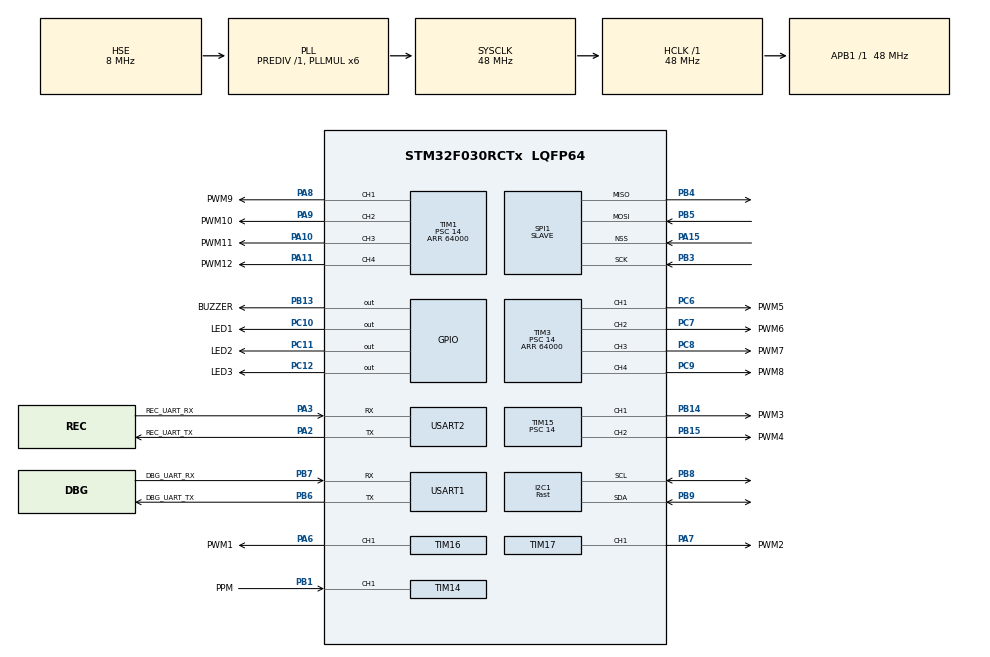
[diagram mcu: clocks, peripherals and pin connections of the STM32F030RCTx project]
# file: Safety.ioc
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I2C1.I2C_Speed_Mode=I2C_Fast
I2C1.Timing=0x0000020B
Mcu.Family=STM32F0
Mcu.Name=STM32F030RCTx
Mcu.Package=LQFP64
NVIC.SPI1_IRQn=true\:0\:0\:false\:false\:true\:true
NVIC.TIM14_IRQn=true\:1\:0\:true\:false\:true\:true
PA10.GPIO_Label=PWM11
PA10.Signal=S_TIM1_CH3
PA11.GPIO_Label=PWM12
PA11.Signal=S_TIM1_CH4
PA13.Mode=Serial_Wire
PA13.Signal=SYS_SWDIO
PA14.Mode=Serial_Wire
PA14.Signal=SYS_SWCLK
PA15.Mode=NSS_Signal_Hard_Input
PA15.Signal=SPI1_NSS
PA2.GPIO_Label=REC_UART_TX
PA2.Mode=Asynchronous
PA2.Signal=USART2_TX
PA3.GPIO_Label=REC_UART_RX
PA3.Mode=Asynchronous
PA3.Signal=USART2_RX
PA6.GPIO_Label=PWM1
PA6.Signal=S_TIM16_CH1
PA7.GPIO_Label=PWM2
PA7.Signal=S_TIM17_CH1
PA8.GPIO_Label=PWM9
PA8.Signal=S_TIM1_CH1
PA9.GPIO_Label=PWM10
PA9.Signal=S_TIM1_CH2
PB1.GPIO_Label=PPM
PB1.GPIO_ModeDefaultPP=GPIO_MODE_AF_PP
PB1.Signal=S_TIM14_CH1
PB13.GPIO_Label=BUZZER
PB13.Signal=GPIO_Output
PB14.GPIO_Label=PWM3
PB14.Signal=S_TIM15_CH1
PB15.GPIO_Label=PWM4
PB15.Signal=S_TIM15_CH2
PB3.Mode=Full_Duplex_Slave
PB3.Signal=SPI1_SCK
PB4.Mode=Full_Duplex_Slave
PB4.Signal=SPI1_MISO
PB5.Mode=Full_Duplex_Slave
PB5.Signal=SPI1_MOSI
PB6.GPIO_Label=DBG_UART_TX
PB6.GPIO_Speed=GPIO_SPEED_FREQ_HIGH
PB6.Mode=Asynchronous
PB6.Signal=USART1_TX
PB7.GPIO_Label=DBG_UART_RX
PB7.Mode=Asynchronous
PB7.Signal=USART1_RX
PB8.Mode=I2C
PB8.Signal=I2C1_SCL
PB9.Mode=I2C
PB9.Signal=I2C1_SDA
PC10.GPIO_Label=LED1
PC10.Signal=GPIO_Output
PC11.GPIO_Label=LED2
PC11.Signal=GPIO_Output
PC12.GPIO_Label=LED3
PC12.Signal=GPIO_Output
PC14OSC32_IN.Mode=LSE-External-Oscillator
PC14OSC32_IN.Signal=RCC_OSC32_IN
PC15OSC32_OUT.Mode=LSE-External-Oscillator
PC15OSC32_OUT.Signal=RCC_OSC32_OUT
PC6.GPIO_Label=PWM5
PC6.Signal=S_TIM3_CH1
PC7.GPIO_Label=PWM6
PC7.Signal=S_TIM3_CH2
PC8.GPIO_Label=PWM7
PC8.Signal=S_TIM3_CH3
PC9.GPIO_Label=PWM8
PC9.Signal=S_TIM3_CH4
PF0-OSC_IN.Mode=HSE-External-Oscillator
PF0-OSC_IN.Signal=RCC_OSC_IN
PF1-OSC_OUT.Mode=HSE-External-Oscillator
PF1-OSC_OUT.Signal=RCC_OSC_OUT
ProjectManager.HeapSize=0x200
ProjectManager.StackSize=0x400
ProjectManager.TargetToolchain=Makefile
RCC.AHBFreq_Value=48000000
RCC.APB1Freq_Value=48000000
RCC.APB1TimFreq_Value=48000000
RCC.HCLKFreq_Value=48000000
RCC.PLLMUL=RCC_PLL_MUL6
RCC.PLLSourceVirtual=RCC_PLLSOURCE_HSE
RCC.SYSCLKFreq_VALUE=48000000
RCC.SYSCLKSource=RCC_SYSCLKSOURCE_PLLCLK
SH.S_TIM14_CH1.0=TIM14_CH1,Input_Capture1_from_TI1
SH.S_TIM15_CH1.0=TIM15_CH1,PWM Generation1 CH1
SH.S_TIM15_CH2.0=TIM15_CH2,PWM Generation2 CH2
SH.S_TIM16_CH1.0=TIM16_CH1,PWM Generation1 CH1
SH.S_TIM17_CH1.0=TIM17_CH1,PWM Generation1 CH1
SH.S_TIM1_CH1.0=TIM1_CH1,PWM Generation1 CH1
SH.S_TIM1_CH2.0=TIM1_CH2,PWM Generation2 CH2
SH.S_TIM1_CH3.0=TIM1_CH3,PWM Generation3 CH3
SH.S_TIM1_CH4.0=TIM1_CH4,PWM Generation4 CH4
SH.S_TIM3_CH1.0=TIM3_CH1,PWM Generation1 CH1
SH.S_TIM3_CH2.0=TIM3_CH2,PWM Generation2 CH2
SH.S_TIM3_CH3.0=TIM3_CH3,PWM Generation3 CH3
SH.S_TIM3_CH4.0=TIM3_CH4,PWM Generation4 CH4
SPI1.CRCCalculation=SPI_CRCCALCULATION_DISABLE
SPI1.DataSize=SPI_DATASIZE_16BIT
SPI1.Direction=SPI_DIRECTION_2LINES
SPI1.Mode=SPI_MODE_SLAVE
SPI1.TIMode=SPI_TIMODE_DISABLE
SPI1.VirtualNSS=VM_NSSHARD
SPI1.VirtualType=VM_SLAVE
TIM1.Channel-PWM\ Generation1\ CH1=TIM_CHANNEL_1
TIM1.Channel-PWM\ Generation2\ CH2=TIM_CHANNEL_2
TIM1.Channel-PWM\ Generation3\ CH3=TIM_CHANNEL_3
TIM1.Channel-PWM\ Generation4\ CH4=TIM_CHANNEL_4
TIM1.OCMode_PWM-PWM\ Generation1\ CH1=TIM_OCMODE_PWM1
TIM1.OCMode_PWM-PWM\ Generation2\ CH2=TIM_OCMODE_PWM1
TIM1.OCMode_PWM-PWM\ Generation3\ CH3=TIM_OCMODE_PWM1
TIM1.OCMode_PWM-PWM\ Generation4\ CH4=TIM_OCMODE_PWM1
TIM1.Period=64000
TIM1.Prescaler=14
TIM1.TIM_MasterSlaveMode=TIM_MASTERSLAVEMODE_DISABLE
TIM14.Channel=TIM_CHANNEL_1
TIM14.Period=48000
TIM14.Prescaler=2
TIM15.Channel-PWM\ Generation1\ CH1=TIM_CHANNEL_1
TIM15.Channel-PWM\ Generation2\ CH2=TIM_CHANNEL_2
TIM15.OCMode_PWM-PWM\ Generation1\ CH1=TIM_OCMODE_PWM1
TIM15.OCMode_PWM-PWM\ Generation2\ CH2=TIM_OCMODE_PWM1
TIM15.Period=64000
TIM15.Prescaler=14
TIM16.Channel=TIM_CHANNEL_1
TIM16.OCMode_PWM=TIM_OCMODE_PWM1
TIM16.Period=64000
TIM16.Prescaler=14
TIM17.Channel=TIM_CHANNEL_1
TIM17.OCMode_PWM=TIM_OCMODE_PWM1
TIM17.Period=64000
TIM17.Prescaler=14
TIM3.Channel-PWM\ Generation1\ CH1=TIM_CHANNEL_1
TIM3.Channel-PWM\ Generation2\ CH2=TIM_CHANNEL_2
TIM3.Channel-PWM\ Generation3\ CH3=TIM_CHANNEL_3
TIM3.Channel-PWM\ Generation4\ CH4=TIM_CHANNEL_4
TIM3.OCMode_PWM-PWM\ Generation1\ CH1=TIM_OCMODE_PWM1
TIM3.OCMode_PWM-PWM\ Generation2\ CH2=TIM_OCMODE_PWM1
TIM3.OCMode_PWM-PWM\ Generation3\ CH3=TIM_OCMODE_PWM1
TIM3.OCMode_PWM-PWM\ Generation4\ CH4=TIM_OCMODE_PWM1
TIM3.Period=64000
TIM3.Prescaler=14
USART1.SwapParam=ADVFEATURE_SWAP_ENABLE
USART1.VirtualMode-Asynchronous=VM_ASYNC
USART1.WordLength=WORDLENGTH_8B
USART2.VirtualMode-Asynchronous=VM_ASYNC
USART2.WordLength=WORDLENGTH_8B
VP_IWDG_VS_IWDG.Mode=IWDG_Activate
VP_TIM14_VS_ClockSourceINT.Mode=Enable_Timer
VP_TIM15_VS_ClockSourceINT.Mode=Internal
VP_TIM16_VS_ClockSourceINT.Mode=Enable_Timer
VP_TIM17_VS_ClockSourceINT.Mode=Enable_Timer
VP_TIM1_VS_ClockSourceINT.Mode=Internal
VP_TIM3_VS_ClockSourceINT.Mode=Internal
board=Safety

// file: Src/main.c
/**
  ******************************************************************************
  * File Name          : main.c
  * Description        : Main program body
  ******************************************************************************
  ** This notice applies to any and all portions of this file
  * that are not between comment pairs USER CODE BEGIN and
  * USER CODE END. Other portions of this file, whether
  * inserted by the user or by software development tools
  * are owned by their respective copyright owners.
  *
  * COPYRIGHT(c) 2017 STMicroelectronics
  *
  * Redistribution and use in source and binary forms, with or without modification,
  * are permitted provided that the following conditions are met:
  *   1. Redistributions of source code must retain the above copyright notice,
  *      this list of conditions and the following disclaimer.
  *   2. Redistributions in binary form must reproduce the above copyright notice,
  *      this list of conditions and the following disclaimer in the documentation
  *      and/or other materials provided with the distribution.
  *   3. Neither the name of STMicroelectronics nor the names of its contributors
  *      may be used to endorse or promote products derived from this software
  *      without specific prior written permission.
  *
  * THIS SOFTWARE IS PROVIDED BY THE COPYRIGHT HOLDERS AND CONTRIBUTORS "AS IS"
  * AND ANY EXPRESS OR IMPLIED WARRANTIES, INCLUDING, BUT NOT LIMITED TO, THE
  * IMPLIED WARRANTIES OF MERCHANTABILITY AND FITNESS FOR A PARTICULAR PURPOSE ARE
  * DISCLAIMED. IN NO EVENT SHALL THE COPYRIGHT HOLDER OR CONTRIBUTORS BE LIABLE
  * FOR ANY DIRECT, INDIRECT, INCIDENTAL, SPECIAL, EXEMPLARY, OR CONSEQUENTIAL
  * DAMAGES (INCLUDING, BUT NOT LIMITED TO, PROCUREMENT OF SUBSTITUTE GOODS OR
  * SERVICES; LOSS OF USE, DATA, OR PROFITS; OR BUSINESS INTERRUPTION) HOWEVER
  * CAUSED AND ON ANY THEORY OF LIABILITY, WHETHER IN CONTRACT, STRICT LIABILITY,
  * OR TORT (INCLUDING NEGLIGENCE OR OTHERWISE) ARISING IN ANY WAY OUT OF THE USE
  * OF THIS SOFTWARE, EVEN IF ADVISED OF THE POSSIBILITY OF SUCH DAMAGE.
  *
  ******************************************************************************
  */

#include "main.h"
#include "stm32f0xx_hal.h"
#include "i2c.h"
#include "iwdg.h"
#include "spi.h"
#include "tim.h"
#include "usart.h"
#include "gpio.h"

/* USER CODE BEGIN Includes */
#include "debug.h"
#include "safety_control.h"

/* USER CODE END Includes */

/* USER CODE BEGIN PV */
/* Private variables ---------------------------------------------------------*/

/* USER CODE END PV */

void SystemClock_Config(void);

/* USER CODE BEGIN PFP */
/* Private function prototypes -----------------------------------------------*/

/* USER CODE END PFP */

int main(void)
{

  /* MCU Configuration----------------------------------------------------------*/

  /* Reset of all peripherals, Initializes the Flash interface and the Systick. */
  HAL_Init();

  /* Configure the system clock */
  SystemClock_Config();

  /* Initialize all configured peripherals */
  MX_GPIO_Init();
  MX_I2C1_Init();
  MX_SPI1_Init();
  MX_TIM1_Init();
  MX_TIM3_Init();
  MX_TIM14_Init();
  MX_TIM15_Init();
  MX_TIM16_Init();
  MX_TIM17_Init();
  MX_USART1_UART_Init();
  MX_USART2_UART_Init();
  MX_IWDG_Init();

  /* USER CODE BEGIN 2 */

  debug("\r\n\r\nStarting up...");
  debug("Compiled on %s at %s", __DATE__, __TIME__);

  HAL_GPIO_WritePin(LED1_GPIO_Port, LED1_Pin, GPIO_PIN_RESET);
  HAL_GPIO_WritePin(LED2_GPIO_Port, LED2_Pin, GPIO_PIN_SET);
  HAL_GPIO_WritePin(LED3_GPIO_Port, LED3_Pin, GPIO_PIN_SET);

  Safety_Init();
  Safety_Run();
  /* USER CODE END 2 */

  /* Infinite loop */
  while (1)
  {

  }

}

/** System Clock Configuration
*/
void SystemClock_Config(void)
{

  RCC_OscInitTypeDef RCC_OscInitStruct;
  RCC_ClkInitTypeDef RCC_ClkInitStruct;
  RCC_PeriphCLKInitTypeDef PeriphClkInit;

    /**Initializes the CPU, AHB and APB busses clocks
    */
  RCC_OscInitStruct.OscillatorType = RCC_OSCILLATORTYPE_HSI|RCC_OSCILLATORTYPE_LSI
                              |RCC_OSCILLATORTYPE_HSE;
  RCC_OscInitStruct.HSEState = RCC_HSE_ON;
  RCC_OscInitStruct.HSIState = RCC_HSI_ON;
  RCC_OscInitStruct.HSICalibrationValue = 16;
  RCC_OscInitStruct.LSIState = RCC_LSI_ON;
  RCC_OscInitStruct.PLL.PLLState = RCC_PLL_ON;
  RCC_OscInitStruct.PLL.PLLSource = RCC_PLLSOURCE_HSE;
  RCC_OscInitStruct.PLL.PLLMUL = RCC_PLL_MUL6;
  RCC_OscInitStruct.PLL.PREDIV = RCC_PREDIV_DIV1;
  if (HAL_RCC_OscConfig(&RCC_OscInitStruct) != HAL_OK)
  {
    _Error_Handler(__FILE__, __LINE__);
  }

    /**Initializes the CPU, AHB and APB busses clocks
    */
  RCC_ClkInitStruct.ClockType = RCC_CLOCKTYPE_HCLK|RCC_CLOCKTYPE_SYSCLK
                              |RCC_CLOCKTYPE_PCLK1;
  RCC_ClkInitStruct.SYSCLKSource = RCC_SYSCLKSOURCE_PLLCLK;
  RCC_ClkInitStruct.AHBCLKDivider = RCC_SYSCLK_DIV1;
  RCC_ClkInitStruct.APB1CLKDivider = RCC_HCLK_DIV1;

  if (HAL_RCC_ClockConfig(&RCC_ClkInitStruct, FLASH_LATENCY_1) != HAL_OK)
  {
    _Error_Handler(__FILE__, __LINE__);
  }

  PeriphClkInit.PeriphClockSelection = RCC_PERIPHCLK_USART1|RCC_PERIPHCLK_I2C1;
  PeriphClkInit.Usart1ClockSelection = RCC_USART1CLKSOURCE_PCLK1;
  PeriphClkInit.I2c1ClockSelection = RCC_I2C1CLKSOURCE_HSI;
  if (HAL_RCCEx_PeriphCLKConfig(&PeriphClkInit) != HAL_OK)
  {
    _Error_Handler(__FILE__, __LINE__);
  }

  HAL_RCC_MCOConfig(RCC_MCO, RCC_MCO1SOURCE_SYSCLK, RCC_MCODIV_1);

    /**Configure the Systick interrupt time
    */
  HAL_SYSTICK_Config(HAL_RCC_GetHCLKFreq()/1000);

    /**Configure the Systick
    */
  HAL_SYSTICK_CLKSourceConfig(SYSTICK_CLKSOURCE_HCLK);

  /* SysTick_IRQn interrupt configuration */
  HAL_NVIC_SetPriority(SysTick_IRQn, 0, 0);
}

void _Error_Handler(char * file, int line)
{
  while(1)
  {
  }
}

/************************ (C) COPYRIGHT STMicroelectronics *****END OF FILE****/
